VERSION ""

NS_ :

BS_:
BU_: Current_Sensor
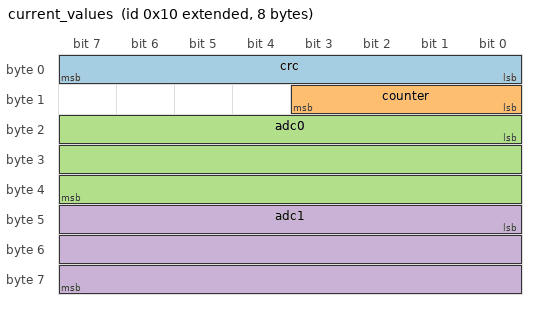
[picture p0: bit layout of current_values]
BO_ 2147483664 current_values: 8 Current_Sensor
   SG_ crc : 7|8@0+ (1,0) [0|1] "" Current_Sensor
   SG_ counter : 11|4@0+ (1,0) [0|1] "" Current_Sensor
   SG_ adc0 : 16|24@1- (0.0001,0) [0|1] "" Current_Sensor
   SG_ adc1 : 40|24@1- (0.0001,0) [0|1] "" Current_Sensor

BO_ 2147483744 unknown_current_value: 8 Current_Sensor
   SG_ adc2 : 0|25@1- (0.0001,0) [0|1] "" Current_Sensor

CM_ BU_ Current_Sensor "Default node if none specified";
BA_DEF_ BO_ "GenMsgBackgroundColor" STRING ;
BA_DEF_ BO_ "GenMsgForegroundColor" STRING ;
BA_DEF_ BO_ "filterlabeling" INT 0 0;
BA_DEF_DEF_ "GenMsgBackgroundColor" "#ffffff";
BA_DEF_DEF_ "GenMsgForegroundColor" "#000000";
BA_DEF_DEF_ "filterlabeling" 1;
